AUTOSAR XML (schema 4-0-3)
standard types defined: UInt32, UInt8
package /AUTOSAR_Platform/DataConstrs
  range DC_UInt8: raw 0..255
package /PATAC/MSM/ComponentTypes
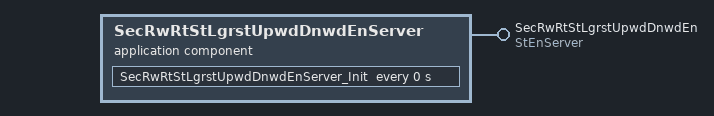
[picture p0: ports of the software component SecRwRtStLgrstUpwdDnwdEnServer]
  application sw component type SecRwRtStLgrstUpwdDnwdEnServer
    provide port SecRwRtStLgrstUpwdDnwdEn: provided-com-specs=[{operation=Clear, queue-length=1}, {operation=Get, queue-length=1}, {operation=Set, queue-length=1}], provided-interface=StEnServer
    behavior SecRwRtStLgrstUpwdDnwdEnServer_InternalBehavior
      operation invoked event OIT_SecRwRtStLgrstUpwdDnwdEn_Clear_SecRwRtStLgrstUpwdDnwdEn_Clear: start-on-event=SecRwRtStLgrstUpwdDnwdEn_Clear, operation=SecRwRtStLgrstUpwdDnwdEn.Clear
      operation invoked event OIT_SecRwRtStLgrstUpwdDnwdEn_Get_SecRwRtStLgrstUpwdDnwdEn_Get: start-on-event=SecRwRtStLgrstUpwdDnwdEn_Get, operation=SecRwRtStLgrstUpwdDnwdEn.Get
      operation invoked event OIT_SecRwRtStLgrstUpwdDnwdEn_Set_SecRwRtStLgrstUpwdDnwdEn_Set: start-on-event=SecRwRtStLgrstUpwdDnwdEn_Set, operation=SecRwRtStLgrstUpwdDnwdEn.Set
      timing event SecRwRtStLgrstUpwdDnwdEnServer_InitEvent: start-on-event=SecRwRtStLgrstUpwdDnwdEnServer_Init, period=0
      4 x runnable:
        SecRwRtStLgrstUpwdDnwdEn_Clear
        SecRwRtStLgrstUpwdDnwdEn_Get
        SecRwRtStLgrstUpwdDnwdEn_Set
        SecRwRtStLgrstUpwdDnwdEnServer_Init
  swc implementation SecRwRtStLgrstUpwdDnwdEnServer_Implementation: behavior=SecRwRtStLgrstUpwdDnwdEnServer_InternalBehavior
    code-descriptors:
      code Default: artifact-descriptors=autosar-engineering-object={short-label=Default, category=SWSRC}
package /PATAC/MSM/ModeAdjust/PortInterface
  client server interface StEnServer
    operation Clear
      arg data: type=UInt8, direction=IN, server-argument-impl-policy=USE-ARGUMENT-TYPE
    operation Get
      arg data: type=UInt32, direction=OUT, server-argument-impl-policy=USE-ARGUMENT-TYPE
    operation Set
      arg data: type=UInt8, direction=IN, server-argument-impl-policy=USE-ARGUMENT-TYPE
